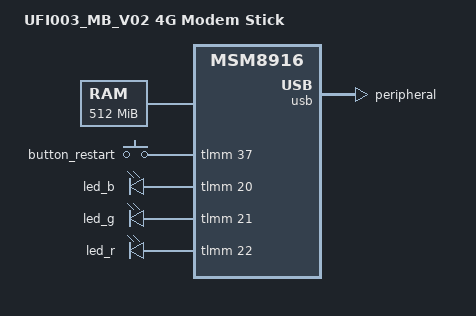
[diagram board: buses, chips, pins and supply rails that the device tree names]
// SPDX-License-Identifier: GPL-2.0-only
/*
 * Zhihe UFI003_MB_V02 4G modem stick (MSM8916)
 *
 * Sold as "410stick" / UFI003-02.  The board-level description is close to
 * msm8916-thwc-ufi001c: same restart key on GPIO 37, same SIM mux on GPIO
 * 0..3.  Only model and compatible differ.
 *
 * The LEDs are NOT an RGB trio.  The vendor tree and an independent teardown
 * writeup agree on four separate indicator LEDs:
 *
 *     WIFI_S  GPIO 20     4G_S   GPIO 22
 *     4G_L2   GPIO 21     4G_L3  GPIO 68
 *
 * GPIO 20/21/22 are correct as wired, but they are WIFI_S / 4G_L2 / 4G_S, not
 * blue / green / red.  The upstream ufi001c labels (led-b/g/r) are kept as the
 * carriers because userspace scripts already reference those names; only the
 * semantics are wrong, not the pin assignment.
 *
 * GPIO 68 (4G_L3) is deliberately not added: the vendor pinctrl group covers
 * only GPIO 0-3, 20-22 and 36, so the fourth LED has a node in the vendor tree
 * but was never configured there.  Whether the part is populated on this PCB
 * is unconfirmed.  See docs/bringup/ufi003-mb-v02/external-references.md.
 *
 * Deliberate deviations from msm8916-thwc-ufi001c.dts:
 *
 *  - memory size is pinned to 512 MiB.  Upstream msm8916.dtsi leaves it at 0
 *    and expects the bootloader to fill it in; the hand-built DTB that this
 *    board shipped with until now hardcoded 512 MiB, so keep the value that is
 *    known to boot.  If a 256 MiB variant of this stick ever shows up, drop
 *    the /memory@80000000 override below.
 *
 *  - USB is forced to peripheral mode.  This is a dongle that is always
 *    plugged into a host, so USB role switching only adds a way to end up in
 *    host mode with no gadget registered.
 *
 *  - venus (video codec) stays disabled: it does not work on these sticks and
 *    this device has no display anyway.
 *
 * Cross-checked against the vendor DTB extracted from the Android firmware
 * (EMMC_3.82.bin -> boot partition -> QCDT, qcom,board-id = <8 0x100>).
 * See docs/bringup/ufi003-mb-v02/vendor-dts-audit.md.  Confirmed identical:
 * mpss_mem base/size, restart key GPIO, USB peripheral mode, eMMC/SD enable
 * states.  Two things that look like mistakes but are not:
 *
 *  - SIM_SEL (GPIO 2) is driven high here.  The vendor tree instead parks it
 *    low and picks the slot through ESIM_SEL (GPIO 0) held high with
 *    ESIM2_SEL (GPIO 3) low.  Both routes land on the external slot, and on
 *    this board the high level on GPIO 2 is what actually works: a card is
 *    detected and registers.  Do not "fix" this to output-low by copying the
 *    vendor tree - that breaks SIM detection.
 *
 *  - The vendor tree defines an ST7735S 128x128 SPI panel on GPIO 23/25 with
 *    mdss_mdp.panel=... in bootargs, but these sticks have no display.  It is
 *    leftover from the reference design (panel width/height are still the
 *    default 480x854).  mdss_spi is also downstream-only with no mainline
 *    driver, so nothing is added for it here.
 */

/dts-v1/;

#include "msm8916-ufi.dtsi"

/ {
	model = "UFI003_MB_V02 4G Modem Stick";
	compatible = "zhihe,ufi003-mb-v02", "qcom,msm8916";

	memory@80000000 {
		reg = <0x0 0x80000000 0x0 0x20000000>;
	};
};

&button_restart {
	gpios = <&tlmm 37 GPIO_ACTIVE_HIGH>;
};

&led_b {
	gpios = <&tlmm 20 GPIO_ACTIVE_HIGH>;
};

&led_g {
	gpios = <&tlmm 21 GPIO_ACTIVE_HIGH>;
};

&led_r {
	gpios = <&tlmm 22 GPIO_ACTIVE_HIGH>;
};

&mpss {
	pinctrl-0 = <&sim_ctrl_default>;
	pinctrl-names = "default";
};

&venus {
	status = "disabled";
};

&usb {
	dr_mode = "peripheral";
	/delete-property/ usb-role-switch;
	/delete-property/ extcon;
};

&usb_hs_phy {
	/delete-property/ extcon;
};

&button_default {
	pins = "gpio37";
	bias-pull-down;
};

&gpio_leds_default {
	pins = "gpio20", "gpio21", "gpio22";
};

/* This selects the external SIM card slot by default */
&tlmm {
	sim_ctrl_default: sim-ctrl-default-state {
		esim-sel-pins {
			pins = "gpio0", "gpio3";
			function = "gpio";
			bias-disable;
			output-low;
		};

		sim-en-pins {
			pins = "gpio1";
			function = "gpio";
			bias-disable;
			output-low;
		};

		sim-sel-pins {
			pins = "gpio2";
			function = "gpio";
			bias-disable;
			output-high;
		};
	};
};
